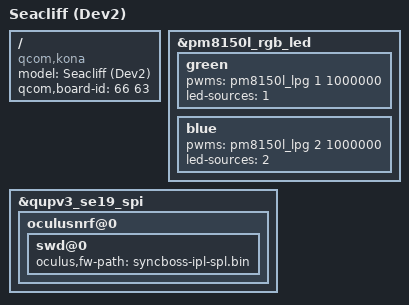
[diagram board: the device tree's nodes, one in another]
/dts-v1/;
/plugin/;

#include "seacliff-p2.dtsi"

/ {
	model = "Seacliff (Dev2)";
	compatible = "qcom,kona";
	qcom,board-id = <66 63>;
};

&pm8150l_rgb_led {
	green {
		pwms = <&pm8150l_lpg 1 1000000>;
		led-sources = <1>;
	};

	blue {
		pwms = <&pm8150l_lpg 2 1000000>;
		led-sources = <2>;
	};
};

&qupv3_se19_spi {
	oculusnrf@0 {
		swd@0 {
			oculus,fw-path = "syncboss-ipl-spl.bin";
		};
	};
};
